# M3HN_L register map
File version: 0.1
Registers are 32-bit, read-write, reset 0x0 unless marked. A register's access mark holds for its fields unless they carry their own. Offsets are from the block's base; [hi:lo] are bit positions; {n}, {i} and the like mark numbered series.

## UART0 — UART
Base 0x400BB000
Same registers: UART1 0x400BB100, UART2 0x400BB200, UART3 0x400BB300, UART4 0x400BBD00, UART5 0x400BBE00
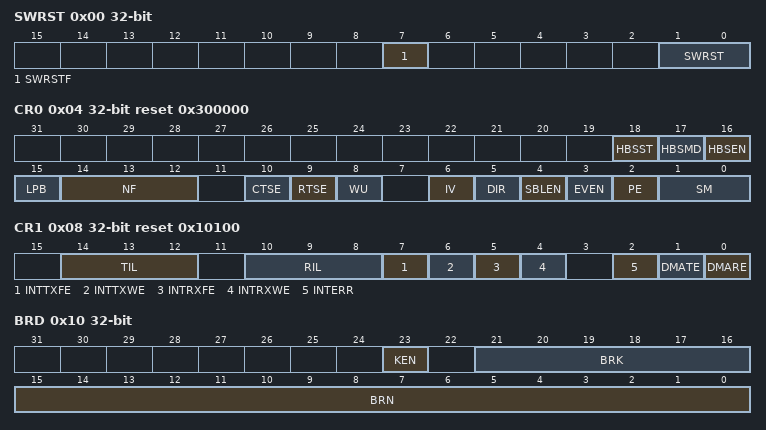
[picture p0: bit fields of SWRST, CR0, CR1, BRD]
0x00 SWRST — UART Software reset register
  [7] SWRSTF ro, [1:0] SWRST wo
0x04 CR0 reset 0x300000 — UART Control register 0
  [18] HBSST, [17] HBSMD, [16] HBSEN, [15] LPB, [14:12] NF, [10] CTSE, [9] RTSE, [8] WU, [6] IV, [5] DIR, [4] SBLEN, [3] EVEN, [2] PE, [1:0] SM
0x08 CR1 reset 0x10100 — UART Control register 1
  [14:12] TIL, [10:8] RIL, [7] INTTXFE, [6] INTTXWE, [5] INTRXFE, [4] INTRXWE, [2] INTERR, [1] DMATE, [0] DMARE
0x0C CLK — UART Clock Control register
  [7:4] PRSEL
0x10 BRD — UART Baud rate register
  [23] KEN, [21:16] BRK, [15:0] BRN
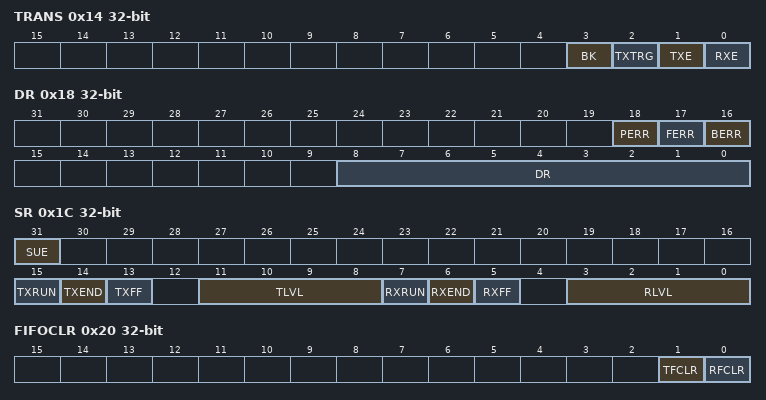
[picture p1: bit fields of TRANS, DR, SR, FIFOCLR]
0x14 TRANS — UART Transfer enable register
  [3] BK, [2] TXTRG, [1] TXE, [0] RXE
0x18 DR (reset mask 0xFFFFFE00) — UART Data register
  [18] PERR ro, [17] FERR ro, [16] BERR ro, [8:0] DR
0x1C SR — UART Status register
  [31] SUE ro, [15] TXRUN ro, [14] TXEND, [13] TXFF, [11:8] TLVL ro, [7] RXRUN ro, [6] RXEND, [5] RXFF, [3:0] RLVL ro
0x20 FIFOCLR — UART FIFO Clear register
  [1] TFCLR wo, [0] RFCLR wo
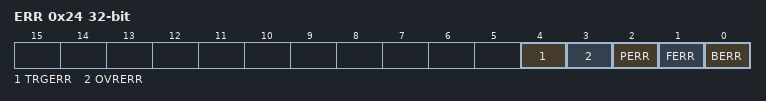
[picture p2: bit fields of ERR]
0x24 ERR — UART Error register
  [4] TRGERR, [3] OVRERR, [2] PERR, [1] FERR, [0] BERR

## SIWD
Base 0x400BB400
0x00 PRO reset 0x1E — SIWD Protect register
  [7:0] PROTECT
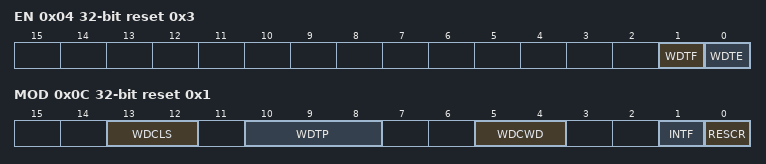
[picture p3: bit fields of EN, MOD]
0x04 EN reset 0x3 — SIWD Enable register
  [1] WDTF ro, [0] WDTE
0x08 CR wo (reset mask 0xFFFFFF00) — SIWD Control register
  [7:0] WDCR
0x0C MOD reset 0x1 — SIWD Mode register
  [13:12] WDCLS, [10:8] WDTP, [5:4] WDCWD, [1] INTF, [0] RESCR
0x10 MONI ro (reset mask 0xC0000000) — SIWD Monitor register
  [29:0] MONI
0x14 OSCCR — SIWD Oscillation control register
  [0] OSCPRO

## DNFA — DNF
Base 0x400BB600
Same registers: DNFB 0x400BB700
0x00 CKCR — DNF clock Control register
  [2:0] NFCKS
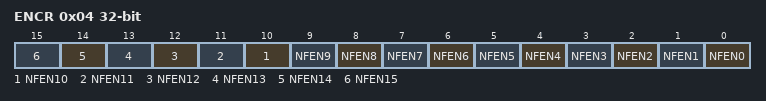
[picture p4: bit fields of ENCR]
0x04 ENCR — DNF Enable register
  [n] NFEN{n} (n=0..15)

## TSEL0 — TRGSEL
Base 0x400BB800
Same registers: TSEL1 0x400BB900
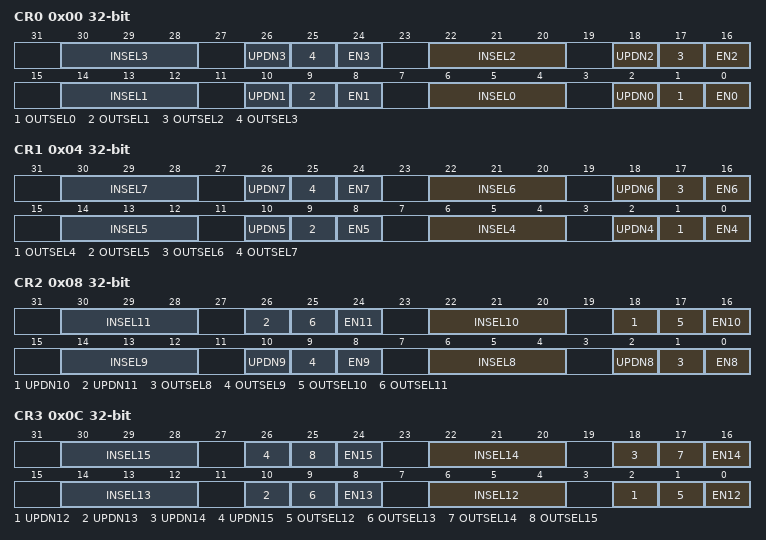
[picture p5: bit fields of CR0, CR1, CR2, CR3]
0x00 CR0 — TRGSEL Control register 0
  [8n+6:8n+4] INSEL{n} (n=0..3), [8n+2] UPDN{n} (n=0..3), [8n+1] OUTSEL{n} (n=0..3), [8n] EN{n} (n=0..3)
0x04 CR1 — TRGSEL Control register 1
  [8n-26:8n-28] INSEL{n} (n=4..7), [8n-30] UPDN{n} (n=4..7), [8n-31] OUTSEL{n} (n=4..7), [8n-32] EN{n} (n=4..7)
0x08 CR2 — TSEL Control register 2
  [8n-58:8n-60] INSEL{n} (n=8..11), [8n-62] UPDN{n} (n=8..11), [8n-63] OUTSEL{n} (n=8..11), [8n-64] EN{n} (n=8..11)
0x0C CR3 — TRGSEL Control register 3
  [8n-90:8n-92] INSEL{n} (n=12..15), [8n-94] UPDN{n} (n=12..15), [8n-95] OUTSEL{n} (n=12..15), [8n-96] EN{n} (n=12..15)
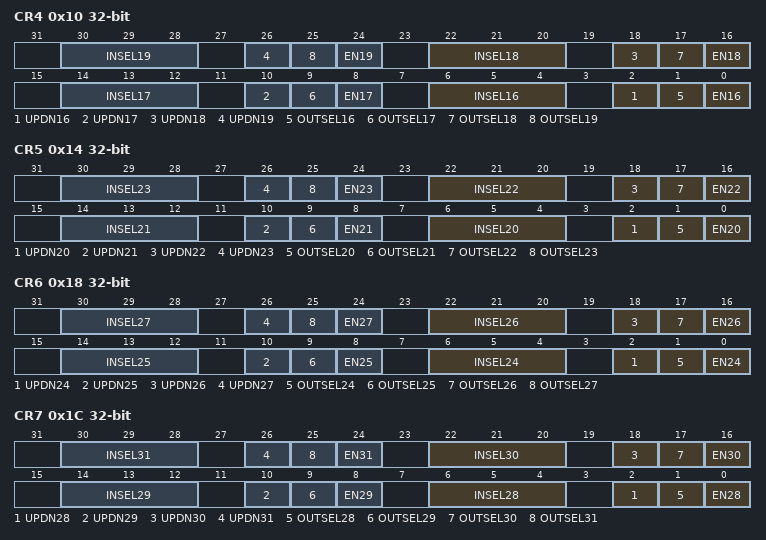
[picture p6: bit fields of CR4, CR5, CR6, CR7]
0x10 CR4 — TRGSEL Control register 4
  [8n-122:8n-124] INSEL{n} (n=16..19), [8n-126] UPDN{n} (n=16..19), [8n-127] OUTSEL{n} (n=16..19), [8n-128] EN{n} (n=16..19)
0x14 CR5 — TRGSEL Control register 5
  [8n-154:8n-156] INSEL{n} (n=20..23), [8n-158] UPDN{n} (n=20..23), [8n-159] OUTSEL{n} (n=20..23), [8n-160] EN{n} (n=20..23)
0x18 CR6 — TRGSEL Control register 6
  [8n-186:8n-188] INSEL{n} (n=24..27), [8n-190] UPDN{n} (n=24..27), [8n-191] OUTSEL{n} (n=24..27), [8n-192] EN{n} (n=24..27)
0x1C CR7 — TRGSEL Control register 7
  [8n-218:8n-220] INSEL{n} (n=28..31), [8n-222] UPDN{n} (n=28..31), [8n-223] OUTSEL{n} (n=28..31), [8n-224] EN{n} (n=28..31)
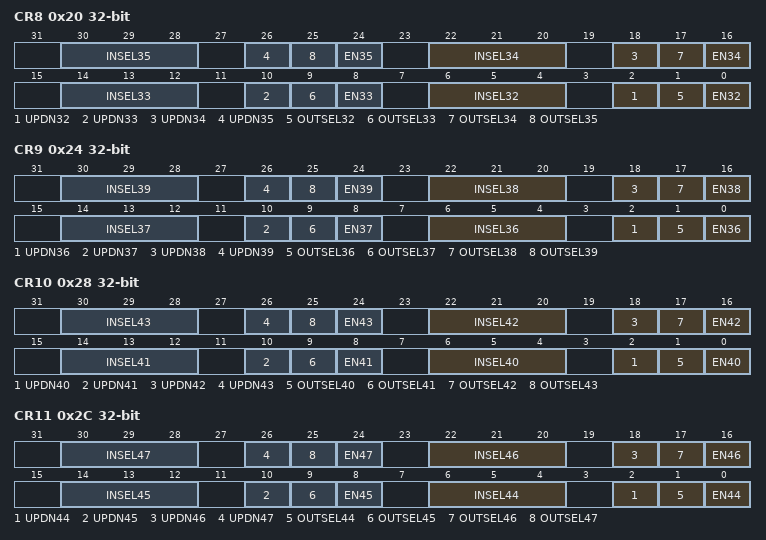
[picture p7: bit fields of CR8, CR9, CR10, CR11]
0x20 CR8 — TRGSEL Control register 8
  [8n-250:8n-252] INSEL{n} (n=32..35), [8n-254] UPDN{n} (n=32..35), [8n-255] OUTSEL{n} (n=32..35), [8n-256] EN{n} (n=32..35)
0x24 CR9 — TRGSEL Control register 9
  [8n-282:8n-284] INSEL{n} (n=36..39), [8n-286] UPDN{n} (n=36..39), [8n-287] OUTSEL{n} (n=36..39), [8n-288] EN{n} (n=36..39)
0x28 CR10 — TRGSEL Control register 10
  [8n-314:8n-316] INSEL{n} (n=40..43), [8n-318] UPDN{n} (n=40..43), [8n-319] OUTSEL{n} (n=40..43), [8n-320] EN{n} (n=40..43)
0x2C CR11 — TRGSEL Control register 11
  [8n-346:8n-348] INSEL{n} (n=44..47), [8n-350] UPDN{n} (n=44..47), [8n-351] OUTSEL{n} (n=44..47), [8n-352] EN{n} (n=44..47)
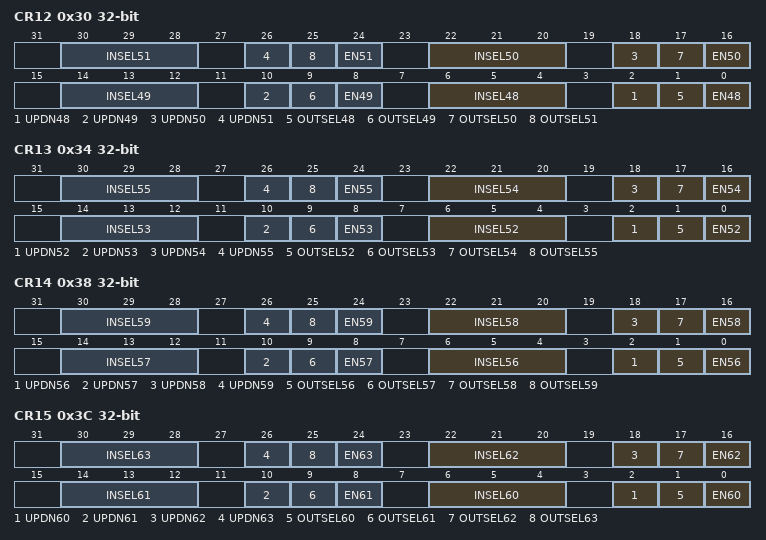
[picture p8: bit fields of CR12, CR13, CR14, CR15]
0x30 CR12 — TRGSEL Control register 12
  [8n-378:8n-380] INSEL{n} (n=48..51), [8n-382] UPDN{n} (n=48..51), [8n-383] OUTSEL{n} (n=48..51), [8n-384] EN{n} (n=48..51)
0x34 CR13 — TRGSEL Control register 13
  [8n-410:8n-412] INSEL{n} (n=52..55), [8n-414] UPDN{n} (n=52..55), [8n-415] OUTSEL{n} (n=52..55), [8n-416] EN{n} (n=52..55)
0x38 CR14 — TRGSEL Control register 14
  [8n-442:8n-444] INSEL{n} (n=56..59), [8n-446] UPDN{n} (n=56..59), [8n-447] OUTSEL{n} (n=56..59), [8n-448] EN{n} (n=56..59)
0x3C CR15 — TRGSEL Control register 15
  [8n-474:8n-476] INSEL{n} (n=60..63), [8n-478] UPDN{n} (n=60..63), [8n-479] OUTSEL{n} (n=60..63), [8n-480] EN{n} (n=60..63)
